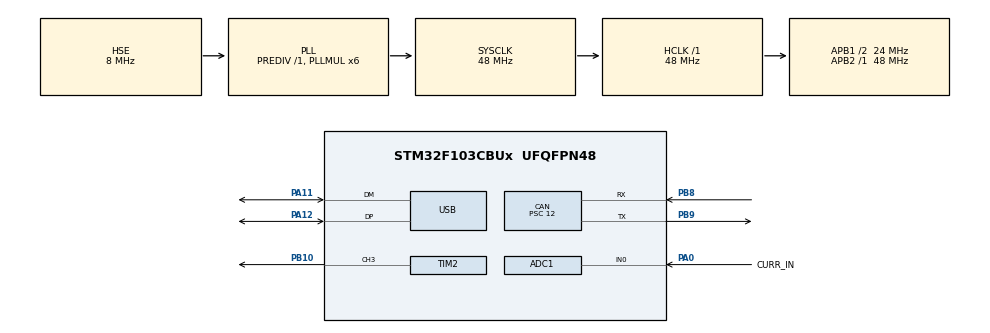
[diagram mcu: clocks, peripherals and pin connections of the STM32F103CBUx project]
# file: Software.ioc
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ADC1.Channel-0\#ChannelRegularConversion=ADC_CHANNEL_0
ADC1.NbrOfConversionFlag=1
ADC1.Rank-0\#ChannelRegularConversion=1
ADC1.SamplingTime-0\#ChannelRegularConversion=ADC_SAMPLETIME_1CYCLE_5
ADC1.master=1
CAN.BS1=CAN_BS1_1TQ
CAN.BS2=CAN_BS2_1TQ
CAN.CalculateBaudRate=666666
CAN.CalculateTimeBit=1500
CAN.CalculateTimeQuantum=500.0
CAN.Prescaler=12
Dma.ADC1.0.Direction=DMA_PERIPH_TO_MEMORY
Dma.ADC1.0.Instance=DMA1_Channel1
Dma.ADC1.0.MemDataAlignment=DMA_MDATAALIGN_HALFWORD
Dma.ADC1.0.MemInc=DMA_MINC_ENABLE
Dma.ADC1.0.Mode=DMA_NORMAL
Dma.ADC1.0.PeriphDataAlignment=DMA_PDATAALIGN_HALFWORD
Dma.ADC1.0.PeriphInc=DMA_PINC_DISABLE
Dma.ADC1.0.Priority=DMA_PRIORITY_LOW
Dma.Request0=ADC1
Mcu.Family=STM32F1
Mcu.Name=STM32F103CBUx
Mcu.Package=UFQFPN48
NVIC.CAN1_RX1_IRQn=true\:0\:0\:false\:false\:true\:true\:true\:true
NVIC.DMA1_Channel1_IRQn=true\:0\:0\:false\:false\:true\:false\:true\:true
NVIC.PriorityGroup=NVIC_PRIORITYGROUP_4
NVIC.USB_LP_CAN1_RX0_IRQn=true\:0\:0\:false\:false\:true\:false\:true\:true
PA0-WKUP.GPIO_Label=CURR_IN
PA0-WKUP.Signal=ADCx_IN0
PA11.Mode=Device
PA11.Signal=USB_DM
PA12.Mode=Device
PA12.Signal=USB_DP
PA13.Mode=JTAG_5_pins
PA13.Signal=SYS_JTMS-SWDIO
PA14.Mode=JTAG_5_pins
PA14.Signal=SYS_JTCK-SWCLK
PA15.Mode=JTAG_5_pins
PA15.Signal=SYS_JTDI
PB10.Signal=S_TIM2_CH3
PB3.Mode=JTAG_5_pins
PB3.Signal=SYS_JTDO-TRACESWO
PB4.Mode=JTAG_5_pins
PB4.Signal=SYS_NJTRST
PB8.Mode=CAN_Activate
PB8.Signal=CAN_RX
PB9.Mode=CAN_Activate
PB9.Signal=CAN_TX
PD0-OSC_IN.Mode=HSE-External-Oscillator
PD0-OSC_IN.Signal=RCC_OSC_IN
PD1-OSC_OUT.Mode=HSE-External-Oscillator
PD1-OSC_OUT.Signal=RCC_OSC_OUT
ProjectManager.HeapSize=0x200
ProjectManager.StackSize=0x400
ProjectManager.TargetToolchain=STM32CubeIDE
RCC.ADCPresc=RCC_ADCPCLK2_DIV4
RCC.AHBFreq_Value=48000000
RCC.APB1CLKDivider=RCC_HCLK_DIV2
RCC.APB1Freq_Value=24000000
RCC.APB1TimFreq_Value=48000000
RCC.APB2Freq_Value=48000000
RCC.APB2TimFreq_Value=48000000
RCC.HCLKFreq_Value=48000000
RCC.PLLMUL=RCC_PLL_MUL6
RCC.SYSCLKFreq_VALUE=48000000
RCC.SYSCLKSource=RCC_SYSCLKSOURCE_PLLCLK
RCC.USBFreq_Value=48000000
SH.ADCx_IN0.0=ADC1_IN0,IN0
SH.S_TIM2_CH3.0=TIM2_CH3,PWM Generation3 CH3
TIM2.Channel-PWM\ Generation3\ CH3=TIM_CHANNEL_3
TIM2.OCFastMode_PWM-PWM\ Generation3\ CH3=TIM_OCFAST_ENABLE
TIM2.Period=100
TIM2.Prescaler=1000
USB_DEVICE.CLASS_NAME_FS=CDC
USB_DEVICE.PRODUCT_STRING_CDC_FS=CLD_v1.0
USB_DEVICE.VirtualMode=Cdc
USB_DEVICE.VirtualModeFS=Cdc_FS
VP_TIM2_VS_ClockSourceINT.Mode=Internal
VP_USB_DEVICE_VS_USB_DEVICE_CDC_FS.Mode=CDC_FS
board=custom

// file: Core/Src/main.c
/* USER CODE BEGIN Header */
/**
  ******************************************************************************
  * @file           : main.c
  * @brief          : Main program body
  ******************************************************************************
  * @attention
  *
  * Copyright (c) 2024 STMicroelectronics.
  * All rights reserved.
  *
  * This software is licensed under terms that can be found in the LICENSE file
  * in the root directory of this software component.
  * If no LICENSE file comes with this software, it is provided AS-IS.
  *
  ******************************************************************************
  */
/* USER CODE END Header */
#include "main.h"
#include "adc.h"
#include "can.h"
#include "dma.h"
#include "tim.h"
#include "usb_device.h"
#include "gpio.h"

void SystemClock_Config(void);

int main(void)
{

  /* MCU Configuration--------------------------------------------------------*/

  /* Reset of all peripherals, Initializes the Flash interface and the Systick. */
  HAL_Init();

  /* Configure the system clock */
  SystemClock_Config();

  /* Initialize all configured peripherals */
  MX_GPIO_Init();
  MX_DMA_Init();
  MX_ADC1_Init();
  MX_CAN_Init();
  MX_USB_DEVICE_Init();
  MX_TIM2_Init();

  /* Infinite loop */
  /* USER CODE BEGIN WHILE */

  char txBuff[8];
  uint8_t count = 0;

  while (1)
  {
    /* USER CODE END WHILE */

  }
}

void SystemClock_Config(void)
{
  RCC_OscInitTypeDef RCC_OscInitStruct = {0};
  RCC_ClkInitTypeDef RCC_ClkInitStruct = {0};
  RCC_PeriphCLKInitTypeDef PeriphClkInit = {0};

  /** Initializes the RCC Oscillators according to the specified parameters
  * in the RCC_OscInitTypeDef structure.
  */
  RCC_OscInitStruct.OscillatorType = RCC_OSCILLATORTYPE_HSE;
  RCC_OscInitStruct.HSEState = RCC_HSE_ON;
  RCC_OscInitStruct.HSEPredivValue = RCC_HSE_PREDIV_DIV1;
  RCC_OscInitStruct.HSIState = RCC_HSI_ON;
  RCC_OscInitStruct.PLL.PLLState = RCC_PLL_ON;
  RCC_OscInitStruct.PLL.PLLSource = RCC_PLLSOURCE_HSE;
  RCC_OscInitStruct.PLL.PLLMUL = RCC_PLL_MUL6;
  if (HAL_RCC_OscConfig(&RCC_OscInitStruct) != HAL_OK)
  {
    Error_Handler();
  }

  /** Initializes the CPU, AHB and APB buses clocks
  */
  RCC_ClkInitStruct.ClockType = RCC_CLOCKTYPE_HCLK|RCC_CLOCKTYPE_SYSCLK
                              |RCC_CLOCKTYPE_PCLK1|RCC_CLOCKTYPE_PCLK2;
  RCC_ClkInitStruct.SYSCLKSource = RCC_SYSCLKSOURCE_PLLCLK;
  RCC_ClkInitStruct.AHBCLKDivider = RCC_SYSCLK_DIV1;
  RCC_ClkInitStruct.APB1CLKDivider = RCC_HCLK_DIV2;
  RCC_ClkInitStruct.APB2CLKDivider = RCC_HCLK_DIV1;

  if (HAL_RCC_ClockConfig(&RCC_ClkInitStruct, FLASH_LATENCY_1) != HAL_OK)
  {
    Error_Handler();
  }
  PeriphClkInit.PeriphClockSelection = RCC_PERIPHCLK_ADC|RCC_PERIPHCLK_USB;
  PeriphClkInit.AdcClockSelection = RCC_ADCPCLK2_DIV4;
  PeriphClkInit.UsbClockSelection = RCC_USBCLKSOURCE_PLL;
  if (HAL_RCCEx_PeriphCLKConfig(&PeriphClkInit) != HAL_OK)
  {
    Error_Handler();
  }
}

void Error_Handler(void)
{
  __disable_irq();
  while (1)
  {
  }
}
